VERSION ""

NS_ :

BS_:

BU_:

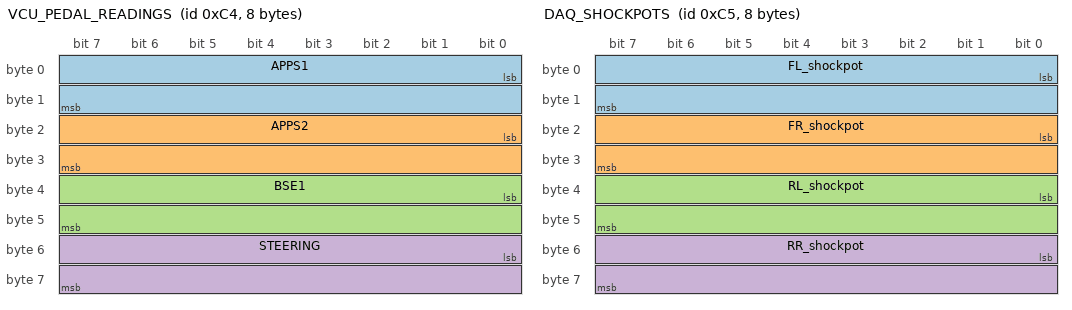
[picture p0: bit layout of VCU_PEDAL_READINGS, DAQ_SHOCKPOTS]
BO_ 196 VCU_PEDAL_READINGS: 8 Vector__XXX
	SG_ APPS1 : 0|16@1+ (0.001220703125,0) [0|12] "V" Vector__XXX
	SG_ APPS2 : 16|16@1+ (0.001220703125,0) [0|12] "V" Vector__XXX
	SG_ BSE1 : 32|16@1+ (0.001220703125,0) [0|12] "V" Vector__XXX
	SG_ STEERING : 48|16@1+ (0.001220703125,0) [0|12] "V" Vector__XXX

BO_ 198 VCU_WHEELSPEED_READINGS: 8 Vector__XXX
	SG_ RPM_FL : 0|32@1+ (0.01,0) [0|4294967296] "RPM" Vector__XXX
	SG_ RPM_FR : 32|32@1+ (0.01,0) [0|4294967296] "RPM" Vector__XXX

BO_ 197 DAQ_SHOCKPOTS: 8 Vector__XXX
	SG_ FL_shockpot : 0|16@1+ (1,0) [0|65535] "" Vector__XXX
	SG_ FR_shockpot : 16|16@1+ (1,0) [0|65535] "" Vector__XXX
	SG_ RL_shockpot : 32|16@1+ (1,0) [0|65535] "" Vector__XXX
	SG_ RR_shockpot : 48|16@1+ (1,0) [0|65535] "" Vector__XXX

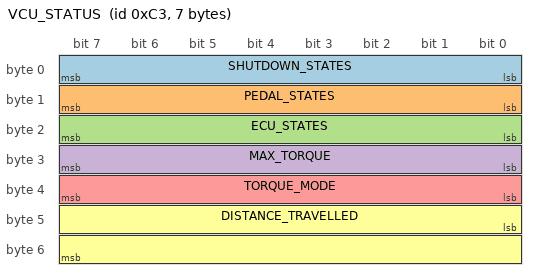
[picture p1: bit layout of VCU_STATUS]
BO_ 195 VCU_STATUS: 7 Vector__XXX
	SG_ SHUTDOWN_STATES : 0|8@1+ (1,0) [0|255] "Bits" Vector__XXX
	SG_ PEDAL_STATES : 8|8@1+ (1,0) [0|255] "Bits" Vector__XXX
	SG_ ECU_STATES : 16|8@1+ (1,0) [0|255] "Bits" Vector__XXX
	SG_ MAX_TORQUE : 24|8@1+ (1,0) [0|255] "Bits" Vector__XXX
	SG_ TORQUE_MODE : 32|8@1+ (1,0) [0|255] "Bits" Vector__XXX
	SG_ DISTANCE_TRAVELLED : 40|16@1+ (1,0) [0|65535] "Bits" Vector__XXX

CM_ BO_ 196 "VCU analog pedal readings";
CM_ SG_ 196 APPS1 "Voltage reading of APPS1";
CM_ SG_ 196 APPS2 "Voltage reading of APPS2";
CM_ BO_ 198 "VCU wheel speed sensor readings";
CM_ SG_ 198 RPM_FL "Front left wheel RPM";
CM_ SG_ 198 RPM_FR "Front right wheel RPM";
CM_ BO_ 197 "DAQ node shonk pot readings";
BA_DEF_ SG_  "SPN" INT 0 524287;
BA_DEF_ BO_  "VFrameFormat" ENUM  "StandardCAN","ExtendedCAN","reserved","J1939PG";
BA_DEF_  "DatabaseVersion" STRING ;
BA_DEF_  "BusType" STRING ;
BA_DEF_  "ProtocolType" STRING ;
BA_DEF_  "DatabaseCompiler" STRING ;
BA_DEF_DEF_  "SPN" 0;
BA_DEF_DEF_  "VFrameFormat" "J1939PG";
BA_DEF_DEF_  "DatabaseVersion" "DEMO PLUS";
BA_DEF_DEF_  "BusType" "";
BA_DEF_DEF_  "ProtocolType" "";
BA_DEF_DEF_  "DatabaseCompiler" "";
BA_ "ProtocolType" "J1939";
BA_ "BusType" "CAN";
BA_ "DatabaseCompiler" "CSS ELECTRONICS (WWW.CSSELECTRONICS.COM)";
BA_ "DatabaseVersion" "1.0.0";
BA_ "SPN" SG_ 2566844926 WheelBasedVehicleSpeed 84;
